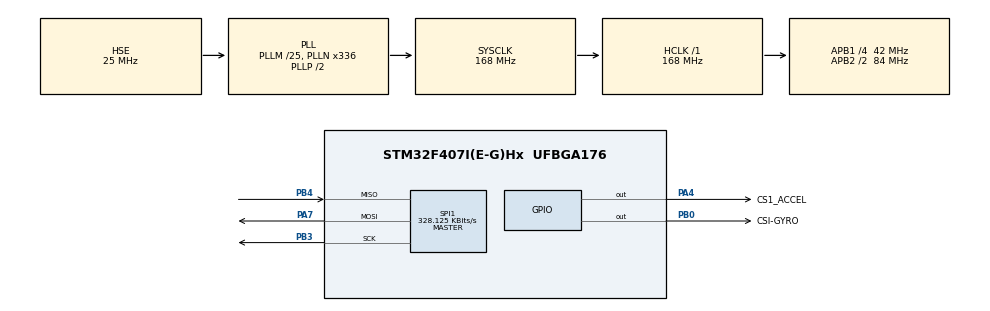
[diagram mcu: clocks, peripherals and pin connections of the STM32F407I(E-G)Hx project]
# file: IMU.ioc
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Mcu.Family=STM32F4
Mcu.Name=STM32F407I(E-G)Hx
Mcu.Package=UFBGA176
NVIC.PriorityGroup=NVIC_PRIORITYGROUP_4
NVIC.TIM6_DAC_IRQn=true\:3\:0\:true\:false\:true\:true\:true\:true
PA13.Mode=Serial_Wire
PA13.Signal=SYS_JTMS-SWDIO
PA14.Mode=Serial_Wire
PA14.Signal=SYS_JTCK-SWCLK
PA4.GPIO_Label=CS1_ACCEL
PA4.PinState=GPIO_PIN_SET
PA4.Signal=GPIO_Output
PA7.Mode=Full_Duplex_Master
PA7.Signal=SPI1_MOSI
PB0.GPIO_Label=CSI-GYRO
PB0.PinState=GPIO_PIN_SET
PB0.Signal=GPIO_Output
PB3.Mode=Full_Duplex_Master
PB3.Signal=SPI1_SCK
PB4.Mode=Full_Duplex_Master
PB4.Signal=SPI1_MISO
PC14-OSC32_IN.Mode=LSE-External-Oscillator
PC14-OSC32_IN.Signal=RCC_OSC32_IN
PC15-OSC32_OUT.Mode=LSE-External-Oscillator
PC15-OSC32_OUT.Signal=RCC_OSC32_OUT
PH0-OSC_IN.Mode=HSE-External-Oscillator
PH0-OSC_IN.Signal=RCC_OSC_IN
PH1-OSC_OUT.Mode=HSE-External-Oscillator
PH1-OSC_OUT.Signal=RCC_OSC_OUT
ProjectManager.HeapSize=0x200
ProjectManager.StackSize=0x400
ProjectManager.TargetToolchain=MDK-ARM V5.32
RCC.48MHZClocksFreq_Value=84000000
RCC.AHBFreq_Value=168000000
RCC.APB1CLKDivider=RCC_HCLK_DIV4
RCC.APB1Freq_Value=42000000
RCC.APB1TimFreq_Value=84000000
RCC.APB2CLKDivider=RCC_HCLK_DIV2
RCC.APB2Freq_Value=84000000
RCC.APB2TimFreq_Value=168000000
RCC.CortexFreq_Value=168000000
RCC.HCLKFreq_Value=168000000
RCC.HSE_VALUE=25000000
RCC.HSI_VALUE=16000000
RCC.PLLM=25
RCC.PLLN=336
RCC.PLLSourceVirtual=RCC_PLLSOURCE_HSE
RCC.SYSCLKFreq_VALUE=168000000
RCC.SYSCLKSource=RCC_SYSCLKSOURCE_PLLCLK
RCC.VCOOutputFreq_Value=336000000
SPI1.BaudRatePrescaler=SPI_BAUDRATEPRESCALER_256
SPI1.CLKPhase=SPI_PHASE_2EDGE
SPI1.CLKPolarity=SPI_POLARITY_HIGH
SPI1.CalculateBaudRate=328.125 KBits/s
SPI1.Direction=SPI_DIRECTION_2LINES
SPI1.Mode=SPI_MODE_MASTER
SPI1.VirtualType=VM_MASTER
TIM6.Period=167
TIM6.Prescaler=999
VP_TIM6_VS_ClockSourceINT.Mode=Enable_Timer
board=custom

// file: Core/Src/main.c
/* USER CODE BEGIN Header */
/**
  ******************************************************************************
  * @file           : main.c
  * @brief          : Main program body
  ******************************************************************************
  * @attention
  *
  * Copyright (c) 2026 STMicroelectronics.
  * All rights reserved.
  *
  * This software is licensed under terms that can be found in the LICENSE file
  * in the root directory of this software component.
  * If no LICENSE file comes with this software, it is provided AS-IS.
  *
  ******************************************************************************
  */
/* USER CODE END Header */
#include "main.h"
#include "spi.h"
#include "tim.h"
#include "gpio.h"

/* USER CODE BEGIN Includes */
#include "bmi088.h"
extern void userCallback(void);
/* USER CODE END Includes */

void SystemClock_Config(void);

int main(void)
{

  /* MCU Configuration--------------------------------------------------------*/

  /* Reset of all peripherals, Initializes the Flash interface and the Systick. */
  HAL_Init();

  /* Configure the system clock */
  SystemClock_Config();

  /* Initialize all configured peripherals */
  MX_GPIO_Init();
  MX_SPI1_Init();
  MX_TIM6_Init();
  /* USER CODE BEGIN 2 */
  bmi088_init();
  HAL_TIM_Base_Start_IT(&htim6);
  /* USER CODE END 2 */

  /* Infinite loop */
  while (1)
  {

  }
}

void SystemClock_Config(void)
{
  RCC_OscInitTypeDef RCC_OscInitStruct = {0};
  RCC_ClkInitTypeDef RCC_ClkInitStruct = {0};

  /** Configure the main internal regulator output voltage
  */
  __HAL_RCC_PWR_CLK_ENABLE();
  __HAL_PWR_VOLTAGESCALING_CONFIG(PWR_REGULATOR_VOLTAGE_SCALE1);

  /** Initializes the RCC Oscillators according to the specified parameters
  * in the RCC_OscInitTypeDef structure.
  */
  RCC_OscInitStruct.OscillatorType = RCC_OSCILLATORTYPE_HSE;
  RCC_OscInitStruct.HSEState = RCC_HSE_ON;
  RCC_OscInitStruct.PLL.PLLState = RCC_PLL_ON;
  RCC_OscInitStruct.PLL.PLLSource = RCC_PLLSOURCE_HSE;
  RCC_OscInitStruct.PLL.PLLM = 25;
  RCC_OscInitStruct.PLL.PLLN = 336;
  RCC_OscInitStruct.PLL.PLLP = RCC_PLLP_DIV2;
  RCC_OscInitStruct.PLL.PLLQ = 4;
  if (HAL_RCC_OscConfig(&RCC_OscInitStruct) != HAL_OK)
  {
    Error_Handler();
  }

  /** Initializes the CPU, AHB and APB buses clocks
  */
  RCC_ClkInitStruct.ClockType = RCC_CLOCKTYPE_HCLK|RCC_CLOCKTYPE_SYSCLK
                              |RCC_CLOCKTYPE_PCLK1|RCC_CLOCKTYPE_PCLK2;
  RCC_ClkInitStruct.SYSCLKSource = RCC_SYSCLKSOURCE_PLLCLK;
  RCC_ClkInitStruct.AHBCLKDivider = RCC_SYSCLK_DIV1;
  RCC_ClkInitStruct.APB1CLKDivider = RCC_HCLK_DIV4;
  RCC_ClkInitStruct.APB2CLKDivider = RCC_HCLK_DIV2;

  if (HAL_RCC_ClockConfig(&RCC_ClkInitStruct, FLASH_LATENCY_5) != HAL_OK)
  {
    Error_Handler();
  }
}

/* USER CODE BEGIN 4 */
void HAL_TIM_PeriodElapsedCallback(TIM_HandleTypeDef *htim)
{
  if (htim==&htim6)
  {
    userCallback();
  }
}
/* USER CODE END 4 */

void Error_Handler(void)
{
  __disable_irq();
  while (1)
  {
  }
}
